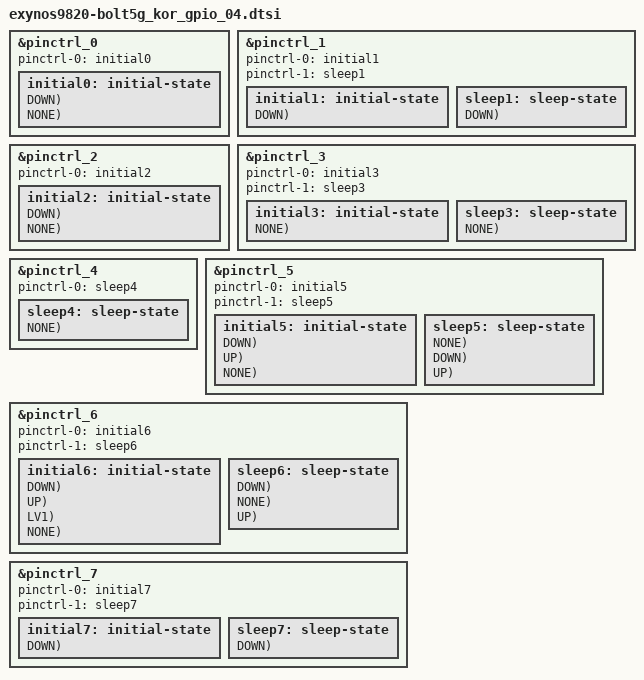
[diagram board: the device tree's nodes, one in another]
/*
 * Copyright (c) 2018 Samsung Electronics Co., Ltd.
 *		http://www.samsung.com
 *
 * This program is free software; you can redistribute it and/or modify
 * it under the terms of the GNU General Public License version 2 as
 * published by the Free Software Foundation.
 */

// Support BOLT5G KOR HW REV0.3 (b0100)

#include "exynos_gpio_config_macros.dtsi"

/*
 * pin banks of exynos9820 pin-controller 0 (ALIVE)
 * GPA0, GPA1, GPA2, GPA3, GPA4
 * GPQ0
 * ETC0
 * Note that do not set sleep state because this is an ALIVE region.
 */
&pinctrl_0 {
	pinctrl-names = "default";
	pinctrl-0 = <&initial0>;
	initial0: initial-state {
		PIN_IN(gpa0-5, DOWN);	/* NC */

		PIN_IN(gpa1-5, NONE);	/* NC */
		PIN_IN(gpa1-7, DOWN);	/* NC */

		PIN_IN(gpa3-0, DOWN);	/* NC */
	};
};

/*
 * pin banks of exynos9820 pin-controller 1 (AUD)
 * GPB0, GPB1, GPB2
 */
&pinctrl_1 {
	pinctrl-names = "default","sleep";
	pinctrl-0 = <&initial1>;
	pinctrl-1 = <&sleep1>;
	initial1: initial-state {
		PIN_IN(gpb0-0, DOWN);	/* NC */
		PIN_IN(gpb0-1, DOWN);	/* NC */
		PIN_IN(gpb0-2, DOWN);	/* NC */
		PIN_IN(gpb0-3, DOWN);	/* NC */
		PIN_IN(gpb0-4, DOWN);	/* NC */

		PIN_IN(gpb1-0, DOWN);	/* NC */
		PIN_IN(gpb1-1, DOWN);	/* NC */
		PIN_IN(gpb1-2, DOWN);	/* NC */
		PIN_IN(gpb1-3, DOWN);	/* NC */
	};
	sleep1: sleep-state {
		PIN_SLP(gpb0-0, INPUT, DOWN);	/* NC */
		PIN_SLP(gpb0-1, INPUT, DOWN);	/* NC */
		PIN_SLP(gpb0-2, INPUT, DOWN);	/* NC */
		PIN_SLP(gpb0-3, INPUT, DOWN);	/* NC */
		PIN_SLP(gpb0-4, INPUT, DOWN);	/* NC */

		PIN_SLP(gpb1-0, INPUT, DOWN);	/* NC */
		PIN_SLP(gpb1-1, INPUT, DOWN);	/* NC */
		PIN_SLP(gpb1-2, INPUT, DOWN);	/* NC */
		PIN_SLP(gpb1-3, INPUT, DOWN);	/* NC */
	};
};

/*
 * pin banks of exynos9820 pin-controller 2 (CMGP)
 * GPM0 ~ GPM10
 * GPM11 ~ GPM20
 * GPM21 ~ GPM30
 * GPM31
 * Note that do not set sleep state because this is an ALIVE region.
 */
&pinctrl_2 {
	pinctrl-names = "default";
	pinctrl-0 = <&initial2>;
	initial2: initial-state {
		PIN_IN(gpm4-0, DOWN);	/* NC */
		PIN_IN(gpm5-0, DOWN);	/* NC */
		PIN_IN(gpm6-0, DOWN);	/* NC */
		PIN_IN(gpm7-0, DOWN);	/* NC */
		PIN_IN(gpm23-0, NONE);	/* NC , UB_CON_DET , VDD_1P8_AP*/
	};
};

/*
 * pin banks of exynos9820 pin-controller 3 (FSYS0)
 * GPF0
 */
&pinctrl_3 {
	pinctrl-names = "default","sleep";
	pinctrl-0 = <&initial3>;
	pinctrl-1 = <&sleep3>;
	initial3: initial-state {
		PIN_IN(gpf0-1, NONE);	/* VDD_1P8_AP */
		PIN_IN(gpf0-3, NONE);	/* VDD_1P8_AP */
		PIN_IN(gpf0-4, NONE);	/* VDD_1P8_AP */
	};
	sleep3: sleep-state {
		PIN_SLP(gpf0-1, INPUT, NONE);	/* VDD_1P8_AP */	
		PIN_SLP(gpf0-3, INPUT, NONE);	/* VDD_1P8_AP */
		PIN_SLP(gpf0-4, INPUT, NONE);	/* VDD_1P8_AP */
	};
};

/*
 * pin banks of exynos9820 pin-controller 4 (FSYS1)
 * GPF1, GPF2, GPF3
 */
&pinctrl_4 {
	pinctrl-names = "sleep";
	pinctrl-0 = <&sleep4>;
	sleep4: sleep-state {
		PIN_SLP(gpf3-0, PREV, NONE);	/* UFS_REFCLK */
		PIN_SLP(gpf3-1, PREV, NONE);	/* UFS_RST_N */
	};
};

/*
 * pin banks of exynos9820 pin-controller 5 (PERIC0)
 * GPP0, GPP1, GPP2, GPP3
 * GPG0, GPG1, GPG2, GPG4
 */
&pinctrl_5 {
	pinctrl-names = "default","sleep";
	pinctrl-0 = <&initial5>;
	pinctrl-1 = <&sleep5>;
	initial5: initial-state {
		PIN_IN(gpp2-4, DOWN);	/* NC */
		PIN_IN(gpp2-5, DOWN);	/* NC */
		PIN_IN(gpp2-6, DOWN);	/* NC */
		PIN_IN(gpp2-7, DOWN);	/* NC */

		PIN_IN(gpp3-0, DOWN);	/* NC */

		PIN_IN(gpg0-0, UP);	/* IFC_SENSE_INT_AP */
		PIN_IN(gpg0-2, DOWN);	/* NC */

		PIN_IN(gpg1-0, DOWN);	/* TSP_ICID */
		PIN_IN(gpg1-1, NONE);	/* HW_REV_M */
		PIN_IN(gpg1-2, NONE);	/* HW_REV3 */
		PIN_IN(gpg1-3, NONE);	/* HW_REV2 */
		PIN_IN(gpg1-4, NONE);	/* HW_REV1 */
		PIN_IN(gpg1-5, NONE);	/* HW_REV0 */
		PIN_IN(gpg1-6, DOWN);	/* NC */

		PIN_IN(gpg2-3, DOWN);	/* NC */

		PIN_IN(gpg4-1, DOWN);	/* NC */
		PIN_IN(gpg4-2, DOWN);	/* NC */
	};
	sleep5: sleep-state {
		PIN_SLP(gpp0-0, PREV, NONE);	/* MUIC_I2C_SCL */
		PIN_SLP(gpp0-1, PREV, NONE);	/* MUIC_I2C_SDA */
		PIN_SLP(gpp1-4, PREV, NONE);	/* TSP_SCL_1P8 */
		PIN_SLP(gpp1-5, PREV, NONE);	/* TSP_SDA_1P8 */
		PIN_SLP(gpp1-6, PREV, NONE);	/* RGB_SCL */
		PIN_SLP(gpp1-7, PREV, NONE);	/* RGB_SDA */

		PIN_SLP(gpp2-4, INPUT, DOWN);	/* NC */
		PIN_SLP(gpp2-5, INPUT, DOWN);	/* NC */
		PIN_SLP(gpp2-6, INPUT, DOWN);	/* NC */
		PIN_SLP(gpp2-7, INPUT, DOWN);	/* NC */

		PIN_SLP(gpp3-4, INPUT, NONE);	/* SMPL_WARN_AP */

		PIN_SLP(gpg0-0, INPUT, UP);  	/* IFC_SENSE_INT_AP */
		PIN_SLP(gpg0-2, INPUT, DOWN);  	/* NC */
		PIN_SLP(gpg0-4, INPUT, UP);  	/* USB3.1_CON_SEL */

		PIN_SLP(gpg1-0, INPUT, DOWN);	/* TSP_ICID */
		PIN_SLP(gpg1-1, INPUT, NONE);	/* HW_REV_M */
		PIN_SLP(gpg1-2, INPUT, NONE);	/* HW_REV3 */
		PIN_SLP(gpg1-3, INPUT, NONE);	/* HW_REV2 */
		PIN_SLP(gpg1-4, INPUT, NONE);	/* HW_REV1 */
		PIN_SLP(gpg1-5, INPUT, NONE);	/* HW_REV0 */
		PIN_SLP(gpg1-6, INPUT, DOWN);	/* NC */
		PIN_SLP(gpg2-2, PREV, NONE);    /* DISP_DET */

		PIN_SLP(gpg4-1, INPUT, DOWN);    /* NC */
		PIN_SLP(gpg4-2, INPUT, DOWN);    /* NC */
	};
};

/*
 * pin banks of exynos9820 pin-controller 6 (PERIC1)
 * GPP4, GPP5, GPP6
 * GPC0, GPC1
 * GPD0
 * GPG3
 * GPH0, GPH1
 */
&pinctrl_6 {
	pinctrl-names = "default","sleep";
	pinctrl-0 = <&initial6>;
	pinctrl-1 = <&sleep6>;
	initial6: initial-state {
		PIN_IN(gpp5-0, DOWN);	/* NC */
		PIN_IN(gpp5-1, DOWN);	/* NC */
		PIN_IN(gpp5-4, DOWN);	/* NC */
		PIN_IN(gpp5-5, DOWN);	/* NC */

		PIN_IN(gpp6-0, DOWN);	/* NC */
		PIN_IN(gpp6-1, DOWN);	/* NC */

		PIN_IN(gpc0-2, DOWN);	/* NC */
		PIN_IN(gpc0-3, DOWN);	/* NC */

		PIN_IN(gpg3-1, UP);	/* WLAN_UART_RXD_DBG */
		PIN_OUT(gpg3-2, LV1);	/* WLAN_UART_TXD_DBG */
		PIN_IN(gpg3-3, NONE);	/* CP_REV1 */
		PIN_IN(gpg3-4, NONE);	/* CP_REV0 */

		PIN_IN(gph0-0, DOWN);	/* NC */
		PIN_IN(gph0-1, DOWN);	/* NC */
		PIN_IN(gph0-2, DOWN);	/* NC */
		PIN_IN(gph0-3, DOWN);	/* NC */
	};
	sleep6:sleep-state {
		PIN_SLP(gpp5-4, INPUT, DOWN);	/* NC */
		PIN_SLP(gpp5-5, INPUT, DOWN);	/* NC */

		PIN_SLP(gpc0-2, INPUT, DOWN);	/* NC */
		PIN_SLP(gpc0-3, INPUT, DOWN);	/* NC */

		PIN_SLP(gpd0-0, PREV, NONE);    /* DISP_TE */
		PIN_SLP(gpd0-2, OUT0, NONE);	/* XBOOTLDO0 */
		PIN_SLP(gpg3-1, INPUT, UP);	/* WLAN_UART_RXD_DBG */
		PIN_SLP(gpg3-2, OUT0, NONE);	/* WLAN_UART_TXD_DBG */
		PIN_SLP(gpg3-3, INPUT, NONE);	/* CP_REV1 */
		PIN_SLP(gpg3-4, INPUT, NONE);	/* CP_REV0 */
	};
};

/*
 * pin banks of exynos9820 pin-controller 7 (VTS)
 * GPV0
 */
&pinctrl_7 {
	pinctrl-names = "default","sleep";
	pinctrl-0 = <&initial7>;
	pinctrl-1 = <&sleep7>;
	initial7: initial-state {
		PIN_IN(gpv0-0, DOWN);	/* NC */
		PIN_IN(gpv0-1, DOWN);	/* NC */
		PIN_IN(gpv0-2, DOWN);	/* NC */
		PIN_IN(gpv0-3, DOWN);	/* NC */
	};
	sleep7:sleep-state {
		PIN_SLP(gpv0-0, INPUT, DOWN);	/* NC */
		PIN_SLP(gpv0-1, INPUT, DOWN);	/* NC */
		PIN_SLP(gpv0-2, INPUT, DOWN);	/* NC */
		PIN_SLP(gpv0-3, INPUT, DOWN);	/* NC */
	};
};
